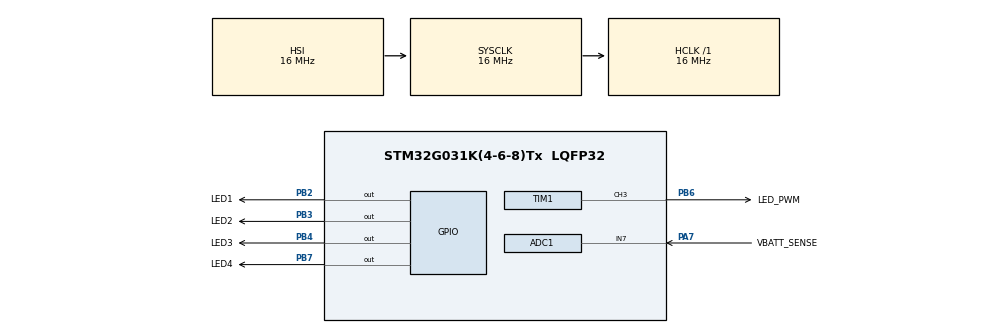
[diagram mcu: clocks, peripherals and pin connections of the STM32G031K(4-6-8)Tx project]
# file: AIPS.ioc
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ADC1.Channel-0\#ChannelRegularConversion=ADC_CHANNEL_7
ADC1.NbrOfConversionFlag=1
ADC1.Rank-0\#ChannelRegularConversion=1
ADC1.SamplingTime-0\#ChannelRegularConversion=ADC_SAMPLINGTIME_COMMON_1
ADC1.SelectedChannel=ADC_CHANNEL_7
ADC1.master=1
Mcu.Family=STM32G0
Mcu.Name=STM32G031K(4-6-8)Tx
Mcu.Package=LQFP32
PA7.GPIO_Label=VBATT_SENSE
PA7.Mode=IN7
PA7.Signal=ADC1_IN7
PB2.GPIO_Label=LED1
PB2.Signal=GPIO_Output
PB3.GPIO_Label=LED2
PB3.Signal=GPIO_Output
PB4.GPIO_Label=LED3
PB4.Signal=GPIO_Output
PB6.GPIO_Label=LED_PWM
PB6.GPIO_Speed=GPIO_SPEED_FREQ_HIGH
PB6.Signal=S_TIM1_CH3
PB7.GPIO_Label=LED4
PB7.Signal=GPIO_Output
ProjectManager.HeapSize=0x200
ProjectManager.StackSize=0x400
ProjectManager.TargetToolchain=CMake
RCC.AHBFreq_Value=16000000
RCC.CortexFreq_Value=16000000
RCC.EXTERNAL_CLOCK_VALUE=12288000
RCC.HCLKFreq_Value=16000000
RCC.HSE_VALUE=8000000
RCC.HSI_VALUE=16000000
RCC.LSE_VALUE=32768
RCC.PLLQ=RCC_PLLQ_DIV4
RCC.SYSCLKFreq_VALUE=16000000
RCC.VCOOutputFreq_Value=128000000
SH.S_TIM1_CH3.0=TIM1_CH3,PWM Generation3 CH3
TIM1.AutoReloadPreload=TIM_AUTORELOAD_PRELOAD_ENABLE
TIM1.Channel-PWM\ Generation3\ CH3=TIM_CHANNEL_3
TIM1.Period=159
TIM1.Prescaler=0
TIM1.Pulse-PWM\ Generation3\ CH3=50
VP_TIM1_VS_ClockSourceINT.Mode=Internal
board=custom

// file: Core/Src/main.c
/* USER CODE BEGIN Header */
/**
 ******************************************************************************
 * @file           : main.c
 * @brief          : Main program body
 ******************************************************************************
 * @attention
 *
 * Copyright (c) 2026 STMicroelectronics.
 * All rights reserved.
 *
 * This software is licensed under terms that can be found in the LICENSE file
 * in the root directory of this software component.
 * If no LICENSE file comes with this software, it is provided AS-IS.
 *
 ******************************************************************************
 */
/* USER CODE END Header */
#include "main.h"

ADC_HandleTypeDef hadc1;

TIM_HandleTypeDef htim1;

void SystemClock_Config(void);
static void MX_GPIO_Init(void);
static void MX_ADC1_Init(void);
static void MX_TIM1_Init(void);

int main(void) {

  /* MCU Configuration--------------------------------------------------------*/

  /* Reset of all peripherals, Initializes the Flash interface and the Systick.
   */
  HAL_Init();

  /* Configure the system clock */
  SystemClock_Config();

  /* Initialize all configured peripherals */
  MX_GPIO_Init();
  MX_ADC1_Init();
  MX_TIM1_Init();
  /* USER CODE BEGIN 2 */
  /* Start PWM on TIM1 Channel 3 */
  HAL_TIM_PWM_Start(&htim1, TIM_CHANNEL_3);
  __HAL_TIM_SET_COMPARE(&htim1, TIM_CHANNEL_3, 0);
  HAL_GPIO_WritePin(LED1_GPIO_Port, LED1_Pin, GPIO_PIN_SET);
  HAL_GPIO_WritePin(LED2_GPIO_Port, LED2_Pin, GPIO_PIN_SET);
  HAL_GPIO_WritePin(LED3_GPIO_Port, LED3_Pin, GPIO_PIN_SET);
  HAL_GPIO_WritePin(LED4_GPIO_Port, LED4_Pin, GPIO_PIN_SET);
  /* USER CODE END 2 */

  /* Infinite loop */
  while (1) {

    /* USER CODE BEGIN 3 */
    /* Set duty cycle to 0-160 */
    for (int i = 0; i <= 160; i++) {

      __HAL_TIM_SET_COMPARE(&htim1, TIM_CHANNEL_3, i);
      HAL_Delay(10);
    }
  }
  /* USER CODE END 3 */
}

void SystemClock_Config(void) {
  RCC_OscInitTypeDef RCC_OscInitStruct = {0};
  RCC_ClkInitTypeDef RCC_ClkInitStruct = {0};

  /** Configure the main internal regulator output voltage
   */
  HAL_PWREx_ControlVoltageScaling(PWR_REGULATOR_VOLTAGE_SCALE1);

  /** Initializes the RCC Oscillators according to the specified parameters
   * in the RCC_OscInitTypeDef structure.
   */
  RCC_OscInitStruct.OscillatorType = RCC_OSCILLATORTYPE_HSI;
  RCC_OscInitStruct.HSIState = RCC_HSI_ON;
  RCC_OscInitStruct.HSIDiv = RCC_HSI_DIV1;
  RCC_OscInitStruct.HSICalibrationValue = RCC_HSICALIBRATION_DEFAULT;
  RCC_OscInitStruct.PLL.PLLState = RCC_PLL_NONE;
  if (HAL_RCC_OscConfig(&RCC_OscInitStruct) != HAL_OK) {
    Error_Handler();
  }

  /** Initializes the CPU, AHB and APB buses clocks
   */
  RCC_ClkInitStruct.ClockType =
      RCC_CLOCKTYPE_HCLK | RCC_CLOCKTYPE_SYSCLK | RCC_CLOCKTYPE_PCLK1;
  RCC_ClkInitStruct.SYSCLKSource = RCC_SYSCLKSOURCE_HSI;
  RCC_ClkInitStruct.AHBCLKDivider = RCC_SYSCLK_DIV1;
  RCC_ClkInitStruct.APB1CLKDivider = RCC_HCLK_DIV1;

  if (HAL_RCC_ClockConfig(&RCC_ClkInitStruct, FLASH_LATENCY_0) != HAL_OK) {
    Error_Handler();
  }
}

static void MX_ADC1_Init(void) {

  ADC_ChannelConfTypeDef sConfig = {0};

  /** Configure the global features of the ADC (Clock, Resolution, Data
   * Alignment and number of conversion)
   */
  hadc1.Instance = ADC1;
  hadc1.Init.ClockPrescaler = ADC_CLOCK_SYNC_PCLK_DIV2;
  hadc1.Init.Resolution = ADC_RESOLUTION_12B;
  hadc1.Init.DataAlign = ADC_DATAALIGN_RIGHT;
  hadc1.Init.ScanConvMode = ADC_SCAN_DISABLE;
  hadc1.Init.EOCSelection = ADC_EOC_SINGLE_CONV;
  hadc1.Init.LowPowerAutoWait = DISABLE;
  hadc1.Init.LowPowerAutoPowerOff = DISABLE;
  hadc1.Init.ContinuousConvMode = DISABLE;
  hadc1.Init.NbrOfConversion = 1;
  hadc1.Init.DiscontinuousConvMode = DISABLE;
  hadc1.Init.ExternalTrigConv = ADC_SOFTWARE_START;
  hadc1.Init.ExternalTrigConvEdge = ADC_EXTERNALTRIGCONVEDGE_NONE;
  hadc1.Init.DMAContinuousRequests = DISABLE;
  hadc1.Init.Overrun = ADC_OVR_DATA_PRESERVED;
  hadc1.Init.SamplingTimeCommon1 = ADC_SAMPLETIME_1CYCLE_5;
  hadc1.Init.SamplingTimeCommon2 = ADC_SAMPLETIME_1CYCLE_5;
  hadc1.Init.OversamplingMode = DISABLE;
  hadc1.Init.TriggerFrequencyMode = ADC_TRIGGER_FREQ_HIGH;
  if (HAL_ADC_Init(&hadc1) != HAL_OK) {
    Error_Handler();
  }

  /** Configure Regular Channel
   */
  sConfig.Channel = ADC_CHANNEL_7;
  sConfig.Rank = ADC_REGULAR_RANK_1;
  sConfig.SamplingTime = ADC_SAMPLINGTIME_COMMON_1;
  if (HAL_ADC_ConfigChannel(&hadc1, &sConfig) != HAL_OK) {
    Error_Handler();
  }
}

static void MX_TIM1_Init(void) {

  TIM_ClockConfigTypeDef sClockSourceConfig = {0};
  TIM_MasterConfigTypeDef sMasterConfig = {0};
  TIM_OC_InitTypeDef sConfigOC = {0};
  TIM_BreakDeadTimeConfigTypeDef sBreakDeadTimeConfig = {0};

  htim1.Instance = TIM1;
  htim1.Init.Prescaler = 0;
  htim1.Init.CounterMode = TIM_COUNTERMODE_UP;
  htim1.Init.Period = 159;
  htim1.Init.ClockDivision = TIM_CLOCKDIVISION_DIV1;
  htim1.Init.RepetitionCounter = 0;
  htim1.Init.AutoReloadPreload = TIM_AUTORELOAD_PRELOAD_ENABLE;
  if (HAL_TIM_Base_Init(&htim1) != HAL_OK) {
    Error_Handler();
  }
  sClockSourceConfig.ClockSource = TIM_CLOCKSOURCE_INTERNAL;
  if (HAL_TIM_ConfigClockSource(&htim1, &sClockSourceConfig) != HAL_OK) {
    Error_Handler();
  }
  if (HAL_TIM_PWM_Init(&htim1) != HAL_OK) {
    Error_Handler();
  }
  sMasterConfig.MasterOutputTrigger = TIM_TRGO_RESET;
  sMasterConfig.MasterOutputTrigger2 = TIM_TRGO2_RESET;
  sMasterConfig.MasterSlaveMode = TIM_MASTERSLAVEMODE_DISABLE;
  if (HAL_TIMEx_MasterConfigSynchronization(&htim1, &sMasterConfig) != HAL_OK) {
    Error_Handler();
  }
  sConfigOC.OCMode = TIM_OCMODE_PWM1;
  sConfigOC.Pulse = 50;
  sConfigOC.OCPolarity = TIM_OCPOLARITY_HIGH;
  sConfigOC.OCNPolarity = TIM_OCNPOLARITY_HIGH;
  sConfigOC.OCFastMode = TIM_OCFAST_DISABLE;
  sConfigOC.OCIdleState = TIM_OCIDLESTATE_RESET;
  sConfigOC.OCNIdleState = TIM_OCNIDLESTATE_RESET;
  if (HAL_TIM_PWM_ConfigChannel(&htim1, &sConfigOC, TIM_CHANNEL_3) != HAL_OK) {
    Error_Handler();
  }
  sBreakDeadTimeConfig.OffStateRunMode = TIM_OSSR_DISABLE;
  sBreakDeadTimeConfig.OffStateIDLEMode = TIM_OSSI_DISABLE;
  sBreakDeadTimeConfig.LockLevel = TIM_LOCKLEVEL_OFF;
  sBreakDeadTimeConfig.DeadTime = 0;
  sBreakDeadTimeConfig.BreakState = TIM_BREAK_DISABLE;
  sBreakDeadTimeConfig.BreakPolarity = TIM_BREAKPOLARITY_HIGH;
  sBreakDeadTimeConfig.BreakFilter = 0;
  sBreakDeadTimeConfig.BreakAFMode = TIM_BREAK_AFMODE_INPUT;
  sBreakDeadTimeConfig.Break2State = TIM_BREAK2_DISABLE;
  sBreakDeadTimeConfig.Break2Polarity = TIM_BREAK2POLARITY_HIGH;
  sBreakDeadTimeConfig.Break2Filter = 0;
  sBreakDeadTimeConfig.Break2AFMode = TIM_BREAK_AFMODE_INPUT;
  sBreakDeadTimeConfig.AutomaticOutput = TIM_AUTOMATICOUTPUT_DISABLE;
  if (HAL_TIMEx_ConfigBreakDeadTime(&htim1, &sBreakDeadTimeConfig) != HAL_OK) {
    Error_Handler();
  }
  HAL_TIM_MspPostInit(&htim1);
}

static void MX_GPIO_Init(void) {
  GPIO_InitTypeDef GPIO_InitStruct = {0};

  /* GPIO Ports Clock Enable */
  __HAL_RCC_GPIOA_CLK_ENABLE();
  __HAL_RCC_GPIOB_CLK_ENABLE();

  /*Configure GPIO pin Output Level */
  HAL_GPIO_WritePin(GPIOB, LED1_Pin | LED2_Pin | LED3_Pin | LED4_Pin,
                    GPIO_PIN_RESET);

  /*Configure GPIO pins : LED1_Pin LED2_Pin LED3_Pin LED4_Pin */
  GPIO_InitStruct.Pin = LED1_Pin | LED2_Pin | LED3_Pin | LED4_Pin;
  GPIO_InitStruct.Mode = GPIO_MODE_OUTPUT_PP;
  GPIO_InitStruct.Pull = GPIO_NOPULL;
  GPIO_InitStruct.Speed = GPIO_SPEED_FREQ_LOW;
  HAL_GPIO_Init(GPIOB, &GPIO_InitStruct);

}

void Error_Handler(void) {
  __disable_irq();
  while (1) {
  }
}

#ifdef USE_FULL_ASSERT
/**
 * @brief  Reports the name of the source file and the source line number
 *         where the assert_param error has occurred.
 * @param  file: pointer to the source file name
 * @param  line: assert_param error line source number
 * @retval None
 */
void assert_failed(uint8_t *file, uint32_t line) {
  /* USER CODE BEGIN 6 */
  /* User can add his own implementation to report the file name and line
     number, ex: printf("Wrong parameters value: file %s on line %d\r\n", file,
     line) */
  /* USER CODE END 6 */
}
#endif /* USE_FULL_ASSERT */
